VERSION ""

NS_ :

BS_:

BU_: CCU PIU DCU VCU
VAL_TABLE_ DriverButton 1 "ON" 0 "OFF" ;
VAL_TABLE_ CoolingPowerModes 4 "FULL" 3 "HIGH" 2 "MEDIUM" 1 "LOW" 0 "OFF" ;
VAL_TABLE_ SensorStatus 4 "SHORTED" 3 "GROUNDED" 2 "OUT_OF_RANGE_UPPER" 1 "OUT_OF_RANGE_LOWER" 0 "NO_FAULT" ;
VAL_TABLE_ FaultStates 1 "FAULT_ACTIVE" 0 "NO_FAULT" ;
VAL_TABLE_ StartupStates 3 "START" 2 "ON" 1 "ACCESSORY" 0 "LOCK" ;

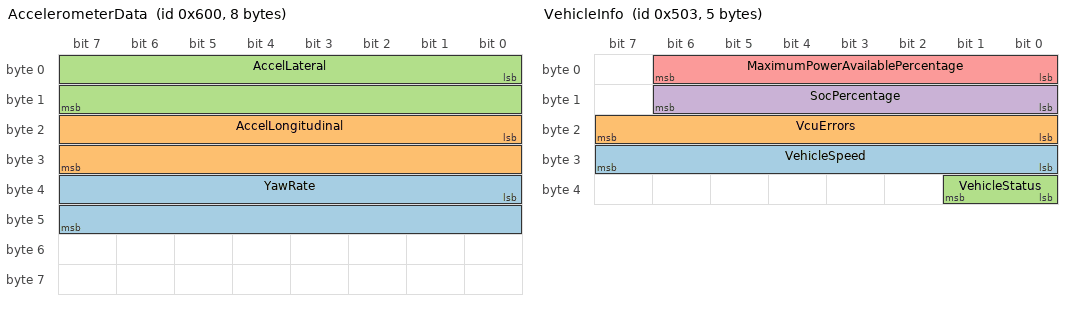
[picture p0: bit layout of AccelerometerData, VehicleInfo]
BO_ 1536 AccelerometerData: 8 PIU
 SG_ YawRate : 32|16@1- (1,0) [0|0] ""  VCU
 SG_ AccelLongitudinal : 16|16@1- (1,0) [0|0] ""  VCU
 SG_ AccelLateral : 0|16@1- (1,0) [0|0] ""  VCU

BO_ 768 LvBatteryData: 8 CCU
 SG_ GlvVoltage : 8|8@1+ (1,0) [0|0] ""  VCU
 SG_ GlvCurrent : 0|8@1+ (1,0) [0|0] ""  VCU

BO_ 1283 VehicleInfo: 5 VCU
 SG_ VehicleSpeed : 24|8@1+ (1,0) [0|255] "km/h"  DCU
 SG_ VcuErrors : 16|8@1+ (1,0) [0|255] ""  DCU
 SG_ VehicleStatus : 32|2@1+ (1,0) [0|3] ""  DCU
 SG_ SocPercentage : 8|7@1+ (1,0) [0|127] "%"  DCU
 SG_ MaximumPowerAvailablePercentage : 0|7@1+ (1,0) [0|127] ""  DCU

BO_ 83 CoolingControllerAnswer: 1 CCU
 SG_ CcuAnswer : 0|8@1+ (1,0) [0|255] ""  VCU

BO_ 85 DashboardAnswer: 1 DCU
 SG_ DcuAnswer : 0|8@1+ (1,0) [0|255] ""  VCU

BO_ 81 PiuControllerAnswer: 1 PIU
 SG_ PiuAnswer : 0|8@1+ (1,0) [0|255] ""  VCU

BO_ 80 PiuControllerQuestion: 1 VCU
 SG_ PiuQuestion : 0|8@1+ (1,0) [0|255] ""  PIU

BO_ 84 DashboardQuestion: 1 VCU
 SG_ DcuQuestion : 0|8@1+ (1,0) [0|255] ""  DCU

BO_ 82 CoolingControllerQuestion: 1 VCU
 SG_ CcuQuestion : 0|8@1+ (1,0) [0|255] ""  CCU

BO_ 1281 DashboardData: 2 DCU
 SG_ GpsVehicleSpeed : 0|12@1+ (0.1,0) [0|409.5] ""  VCU

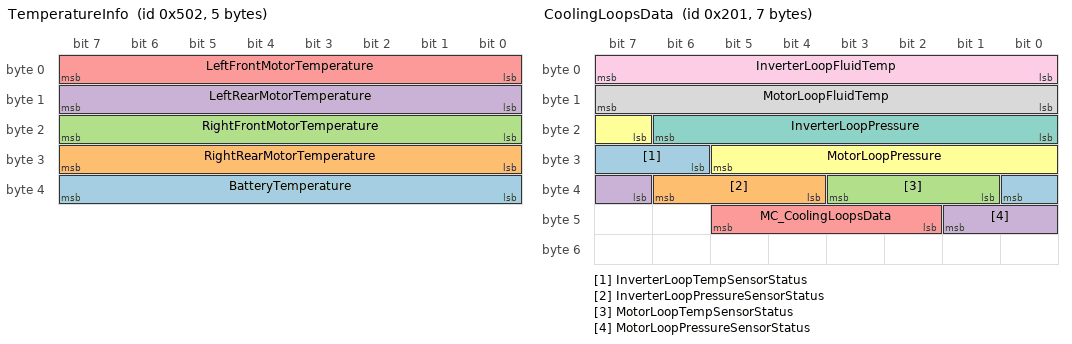
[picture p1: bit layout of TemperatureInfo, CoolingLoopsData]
BO_ 1282 TemperatureInfo: 5 VCU
 SG_ BatteryTemperature : 32|8@1+ (1,-20) [-20|235] "°C" Vector__XXX
 SG_ RightRearMotorTemperature : 24|8@1+ (1,-20) [-20|235] "°C"  DCU
 SG_ RightFrontMotorTemperature : 16|8@1+ (1,-20) [-20|235] "°C"  DCU
 SG_ LeftRearMotorTemperature : 8|8@1+ (1,-20) [-20|235] "°C"  DCU
 SG_ LeftFrontMotorTemperature : 0|8@1+ (1,-20) [-20|235] "°C"  DCU

BO_ 513 CoolingLoopsData: 7 CCU
 SG_ InverterLoopTempSensorStatus : 30|3@1+ (1,0) [0|7] ""  VCU
 SG_ InverterLoopPressureSensorStatus : 36|3@1+ (1,0) [0|7] ""  VCU
 SG_ MotorLoopTempSensorStatus : 33|3@1+ (1,0) [0|7] ""  VCU
 SG_ MotorLoopPressureSensorStatus : 39|3@1+ (1,0) [0|7] ""  VCU
 SG_ MC_CoolingLoopsData : 42|4@1+ (1,0) [0|15] ""  VCU
 SG_ MotorLoopPressure : 23|7@1+ (1,0) [0|127] "kPa"  VCU
 SG_ InverterLoopPressure : 16|7@1+ (1,0) [0|127] "kPa"  VCU
 SG_ MotorLoopFluidTemp : 8|8@1+ (1,-20) [-20|235] "°C"  VCU
 SG_ InverterLoopFluidTemp : 0|8@1+ (1,-20) [-20|235] "°C"  VCU

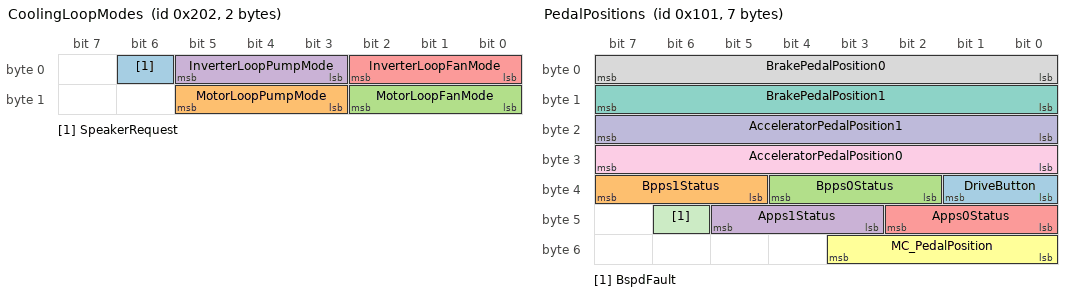
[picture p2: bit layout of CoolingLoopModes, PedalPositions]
BO_ 514 CoolingLoopModes: 2 VCU
 SG_ SpeakerRequest : 6|1@1+ (1,0) [0|1] ""  CCU
 SG_ MotorLoopPumpMode : 11|3@1+ (1,0) [0|100] ""  CCU
 SG_ MotorLoopFanMode : 8|3@1+ (1,0) [0|100] ""  CCU
 SG_ InverterLoopPumpMode : 3|3@1+ (1,0) [0|100] ""  CCU
 SG_ InverterLoopFanMode : 0|3@1+ (1,0) [0|255] ""  CCU

BO_ 257 PedalPositions: 7 PIU
 SG_ DriveButton : 32|2@1+ (1,0) [0|3] ""  VCU
 SG_ Bpps1Status : 37|3@1+ (1,0) [0|7] ""  VCU
 SG_ Bpps0Status : 34|3@1+ (1,0) [0|7] ""  VCU
 SG_ Apps1Status : 43|3@1+ (1,0) [0|7] ""  VCU
 SG_ Apps0Status : 40|3@1+ (1,0) [0|7] ""  VCU
 SG_ MC_PedalPosition : 48|4@1+ (1,0) [0|15] ""  VCU
 SG_ BrakePedalPosition1 : 8|8@1+ (1,0) [0|255] "%"  VCU
 SG_ BrakePedalPosition0 : 0|8@1+ (1,0) [0|255] "%"  VCU
 SG_ AcceleratorPedalPosition0 : 24|8@1+ (1,0) [0|255] "%"  VCU
 SG_ AcceleratorPedalPosition1 : 16|8@1+ (1,0) [0|255] "%"  VCU
 SG_ BspdFault : 46|1@1+ (1,0) [0|1] ""  VCU

CM_ SG_ 1283 VcuErrors "Errors and warnings are represented by specific code numbers, and are reported by the VCU.";
BA_DEF_  "BusType" STRING ;
BA_DEF_DEF_  "BusType" "";
BA_ "BusType" "CAN";
VAL_ 1283 VehicleStatus 2 "ON" 1 "ACCESSORY" 0 "LOCK" ;
VAL_ 513 InverterLoopTempSensorStatus 4 "SHORTED" 3 "GROUNDED" 2 "OUT_OF_RANGE_UPPER" 1 "OUT_OF_RANGE_LOWER" 0 "NO_FAULT" ;
VAL_ 513 InverterLoopPressureSensorStatus 4 "SHORTED" 3 "GROUNDED" 2 "OUT_OF_RANGE_UPPER" 1 "OUT_OF_RANGE_LOWER" 0 "NO_FAULT" ;
VAL_ 513 MotorLoopTempSensorStatus 4 "SHORTED" 3 "GROUNDED" 2 "OUT_OF_RANGE_UPPER" 1 "OUT_OF_RANGE_LOWER" 0 "NO_FAULT" ;
VAL_ 513 MotorLoopPressureSensorStatus 4 "SHORTED" 3 "GROUNDED" 2 "OUT_OF_RANGE_UPPER" 1 "OUT_OF_RANGE_LOWER" 0 "NO_FAULT" ;
VAL_ 514 SpeakerRequest 1 "ON" 0 "OFF" ;
VAL_ 514 MotorLoopPumpMode 4 "FULL" 3 "HIGH" 2 "MEDIUM" 1 "LOW" 0 "OFF" ;
VAL_ 514 MotorLoopFanMode 4 "FULL" 3 "HIGH" 2 "MEDIUM" 1 "LOW" 0 "OFF" ;
VAL_ 514 InverterLoopPumpMode 4 "FULL" 3 "HIGH" 2 "MEDIUM" 1 "LOW" 0 "OFF" ;
VAL_ 514 InverterLoopFanMode 4 "FULL" 3 "HIGH" 2 "MEDIUM" 1 "LOW" 0 "OFF" ;
VAL_ 257 DriveButton 2 "SHUTDOWN" 1 "ON" 0 "OFF" ;
VAL_ 257 Bpps1Status 4 "SHORTED" 3 "GROUNDED" 2 "OUT_OF_RANGE_UPPER" 1 "OUT_OF_RANGE_LOWER" 0 "NO_FAULT" ;
VAL_ 257 Bpps0Status 4 "SHORTED" 3 "GROUNDED" 2 "OUT_OF_RANGE_UPPER" 1 "OUT_OF_RANGE_LOWER" 0 "NO_FAULT" ;
VAL_ 257 Apps1Status 4 "SHORTED" 3 "GROUNDED" 2 "OUT_OF_RANGE_UPPER" 1 "OUT_OF_RANGE_LOWER" 0 "NO_FAULT" ;
VAL_ 257 Apps0Status 4 "SHORTED" 3 "GROUNDED" 2 "OUT_OF_RANGE_UPPER" 1 "OUT_OF_RANGE_LOWER" 0 "NO_FAULT" ;
VAL_ 257 BspdFault 1 "FAULT_ACTIVE" 0 "NO_FAULT" ;
